# CC1314R10 register map
File version: 1.0
CPU: CM33 1.0, other endian, MPU, FPU, 3 interrupt priority bits
Registers are 32-bit, read-write, reset 0x0 unless marked. A register's access mark holds for its fields unless they carry their own. Offsets are from the block's base; [hi:lo] are bit positions; {n}, {i} and the like mark numbered series.

## CPU_ITM — Cortex-M's Instrumentation Trace Macrocell (ITM)
Base 0xE0000000
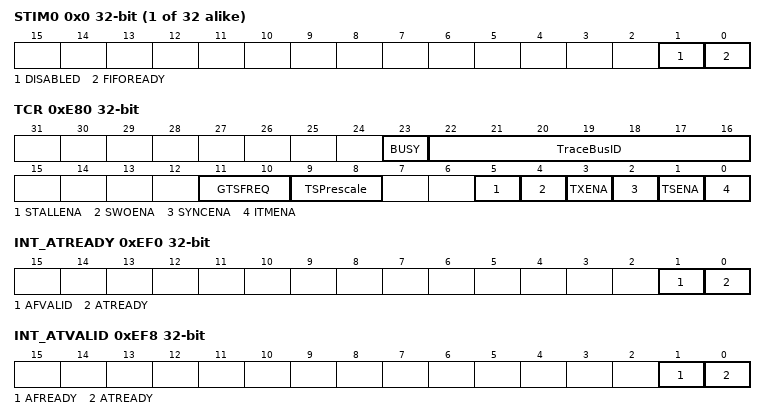
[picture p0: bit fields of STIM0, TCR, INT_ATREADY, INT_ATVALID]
{0x0+4i} STIM{i} (i=0..31) — Provides the interface for generating Instrumentation packets
  [1] DISABLED ro — [1:1] Indicates whether the Stimulus Port is enabled or disabled
  [0] FIFOREADY ro — [0:0] Indicates whether the Stimulus Port can accept data
0xE00 TER0 — Provide an individual enable bit for each ITM_STIM register
  [31:0] STIMENA — [31:0] For STIMENA[m] in ITM_TER*n, controls whether ITM_STIM(32*n + m) is enabled
0xE40 TPR — Controls which stimulus ports can be accessed by unprivileged code
  [31:0] PRIVMASK — [31:0] For PRIVMASK[m], defines the access permissions of ITM_STIM Stimulus Ports 8m to 8m+7 inclusive
0xE80 TCR — Configures and controls transfers through the ITM interface
  [23] BUSY ro — [23:23] Indicates whether the ITM is currently processing events
  [22:16] TraceBusID — [22:16] Identifier for multi-source trace stream formatting. If multi-source trace is in use, the debugger must write a unique non-zero trace ID value to this field
  [11:10] GTSFREQ — [11:10] Defines how often the ITM generates a global timestamp, based on the global timestamp clock frequency, or disables generation of global timestamps
  [9:8] TSPrescale — [9:8] Local timestamp prescaler, used with the trace packet reference clock
  [5] STALLENA — [5:5] Stall the PE to guarantee delivery of Data Trace packets.
  [4] SWOENA — [4:4] Enables asynchronous clocking of the timestamp counter
  [3] TXENA — [3:3] Enables forwarding of hardware event packet from the DWT unit to the ITM for output to the TPIU
  [2] SYNCENA — [2:2] Enables Synchronization packet transmission for a synchronous TPIU
  [1] TSENA — [1:1] Enables Local timestamp generation
  [0] ITMENA — [0:0] Enables the ITM
0xEF0 INT_ATREADY — Integration Mode: Read ATB Ready
  [1] AFVALID ro — [1:1] A read of this bit returns the value of AFVALID
  [0] ATREADY ro — [0:0] A read of this bit returns the value of ATREADY
0xEF8 INT_ATVALID — Integration Mode: Write ATB Valid
  [1] AFREADY wo — [1:1] A write to this bit gives the value of AFREADY
  [0] ATREADY wo — [0:0] A write to this bit gives the value of ATVALID
0xF00 ITCTRL — Integration Mode Control Register
  [0] IME — [0:0] Integration mode enable bit - The possible values are: 0 - The trace unit is not in integration mode. 1 - The trace unit is in integration mode. This mode enables: A debug agent to perform topology detection. SoC test software to perform integration testing.
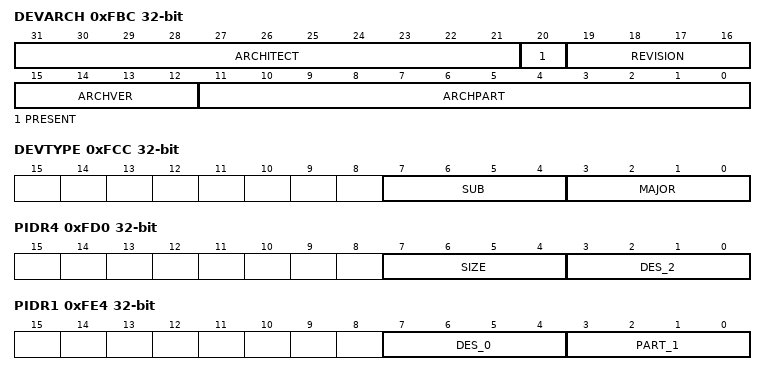
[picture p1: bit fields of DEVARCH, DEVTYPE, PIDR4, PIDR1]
0xFBC DEVARCH — Provides CoreSight discovery information for the ITM
  [31:21] ARCHITECT ro — [31:21] Defines the architect of the component. Bits [31:28] are the JEP106 continuation code (JEP106 bank ID, minus 1) and bits [27:21] are the JEP106 ID code.
  [20] PRESENT ro — [20:20] Defines that the DEVARCH register is present
  [19:16] REVISION ro — [19:16] Defines the architecture revision of the component
  [15:12] ARCHVER ro — [15:12] Defines the architecture version of the component
  [11:0] ARCHPART ro — [11:0] Defines the architecture of the component
0xFCC DEVTYPE — Provides CoreSight discovery information for the ITM
  [7:4] SUB ro — [7:4] Component sub-type
  [3:0] MAJOR ro — [3:0] Component major type
0xFD0 PIDR4 — Provides CoreSight discovery information for the ITM
  [7:4] SIZE ro — [7:4] See CoreSight Architecture Specification
  [3:0] DES_2 ro — [3:0] See CoreSight Architecture Specification
{0xFC0+4i} PIDR{i} (i=5..7) — Provides CoreSight discovery information for the ITM
0xFE0 PIDR0 — Provides CoreSight discovery information for the ITM
  [7:0] PART_0 ro — [7:0] See CoreSight Architecture Specification
0xFE4 PIDR1 — Provides CoreSight discovery information for the ITM
  [7:4] DES_0 ro — [7:4] See CoreSight Architecture Specification
  [3:0] PART_1 ro — [3:0] See CoreSight Architecture Specification
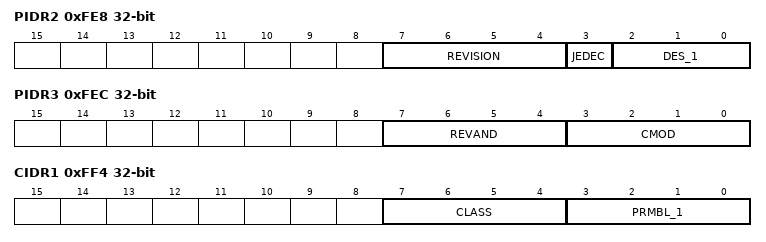
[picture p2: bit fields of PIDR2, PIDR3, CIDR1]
0xFE8 PIDR2 — Provides CoreSight discovery information for the ITM
  [7:4] REVISION ro — [7:4] See CoreSight Architecture Specification
  [3] JEDEC ro — [3:3] See CoreSight Architecture Specification
  [2:0] DES_1 ro — [2:0] See CoreSight Architecture Specification
0xFEC PIDR3 — Provides CoreSight discovery information for the ITM
  [7:4] REVAND ro — [7:4] See CoreSight Architecture Specification
  [3:0] CMOD ro — [3:0] See CoreSight Architecture Specification
0xFF0 CIDR0 — Provides CoreSight discovery information for the ITM
  [7:0] PRMBL_0 ro — [7:0] See CoreSight Architecture Specification
0xFF4 CIDR1 — Provides CoreSight discovery information for the ITM
  [7:4] CLASS ro — [7:4] See CoreSight Architecture Specification
  [3:0] PRMBL_1 ro — [3:0] See CoreSight Architecture Specification
0xFF8 CIDR2 — Provides CoreSight discovery information for the ITM
  [7:0] PRMBL_2 ro — [7:0] See CoreSight Architecture Specification
0xFFC CIDR3 — Provides CoreSight discovery information for the ITM
  [7:0] PRMBL_3 ro — [7:0] See CoreSight Architecture Specification
